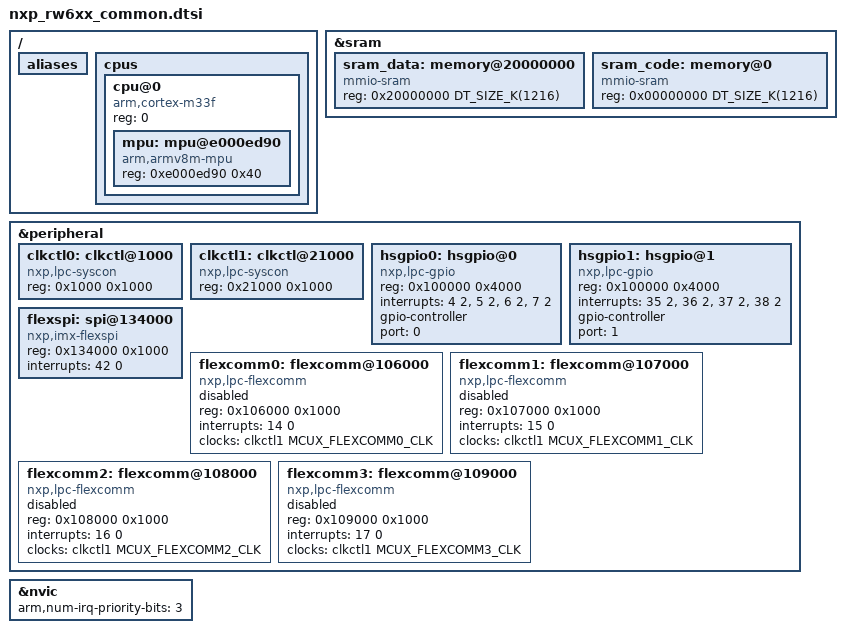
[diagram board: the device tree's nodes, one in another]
/*
 * Copyright 2022 NXP
 *
 * SPDX-License-Identifier: Apache-2.0
 */

#include <mem.h>
#include <arm/armv8-m.dtsi>
#include <zephyr/dt-bindings/clock/mcux_lpc_syscon_clock.h>
#include <dt-bindings/gpio/gpio.h>
#include <dt-bindings/i2c/i2c.h>

/ {
	aliases {
	};

	cpus {
		#address-cells = <1>;
		#size-cells = <0>;

		cpu@0 {
			compatible = "arm,cortex-m33f";
			reg = <0>;
			#address-cells = <1>;
			#size-cells = <1>;

			mpu: mpu@e000ed90 {
				compatible = "arm,armv8m-mpu";
				reg = <0xe000ed90 0x40>;
			};
		};
	};



};

&sram {
	#address-cells = <1>;
	#size-cells = <1>;

	sram_data: memory@20000000 {
		compatible = "mmio-sram";
		reg = <0x20000000 DT_SIZE_K(1216)>;
	};

	sram_code: memory@0 {
		compatible = "mmio-sram";
		reg = <0x00000000 DT_SIZE_K(1216)>;
	};
};

&peripheral {
	#address-cells = <1>;
	#size-cells = <1>;

	clkctl0: clkctl@1000 {
		compatible = "nxp,lpc-syscon";
		reg = <0x1000 0x1000>;
		#clock-cells = <1>;
	};

	clkctl1: clkctl@21000 {
		compatible = "nxp,lpc-syscon";
		reg = <0x21000 0x1000>;
		#clock-cells = <1>;
	};

	hsgpio0: hsgpio@0 {
		compatible = "nxp,lpc-gpio";
		reg = <0x100000 0x4000>;
		interrupts = <4 2>,<5 2>,<6 2>,<7 2>;
		gpio-controller;
		#gpio-cells = <2>;
		port = <0>;
	};

	hsgpio1: hsgpio@1 {
		compatible = "nxp,lpc-gpio";
		reg = <0x100000 0x4000>;
		interrupts = <35 2>,<36 2>,<37 2>,<38 2>;
		gpio-controller;
		#gpio-cells = <2>;
		port = <1>;
	};

	flexspi: spi@134000 {
		compatible = "nxp,imx-flexspi";
		reg = <0x134000 0x1000>;
		interrupts = <42 0>;
		#address-cells = <1>;
		#size-cells = <0>;
	};

	flexcomm0: flexcomm@106000 {
		compatible = "nxp,lpc-flexcomm";
		reg = <0x106000 0x1000>;
		interrupts = <14 0>;
		clocks = <&clkctl1 MCUX_FLEXCOMM0_CLK>;
		status = "disabled";
	};

	flexcomm1: flexcomm@107000 {
		compatible = "nxp,lpc-flexcomm";
		reg = <0x107000 0x1000>;
		interrupts = <15 0>;
		clocks = <&clkctl1 MCUX_FLEXCOMM1_CLK>;
		status = "disabled";
	};

	flexcomm2: flexcomm@108000 {
		compatible = "nxp,lpc-flexcomm";
		reg = <0x108000 0x1000>;
		interrupts = <16 0>;
		clocks = <&clkctl1 MCUX_FLEXCOMM2_CLK>;
		status = "disabled";
	};

	flexcomm3: flexcomm@109000 {
		compatible = "nxp,lpc-flexcomm";
		reg = <0x109000 0x1000>;
		interrupts = <17 0>;
		clocks = <&clkctl1 MCUX_FLEXCOMM3_CLK>;
		status = "disabled";
	};

};

&nvic {
	arm,num-irq-priority-bits = <3>;
};
